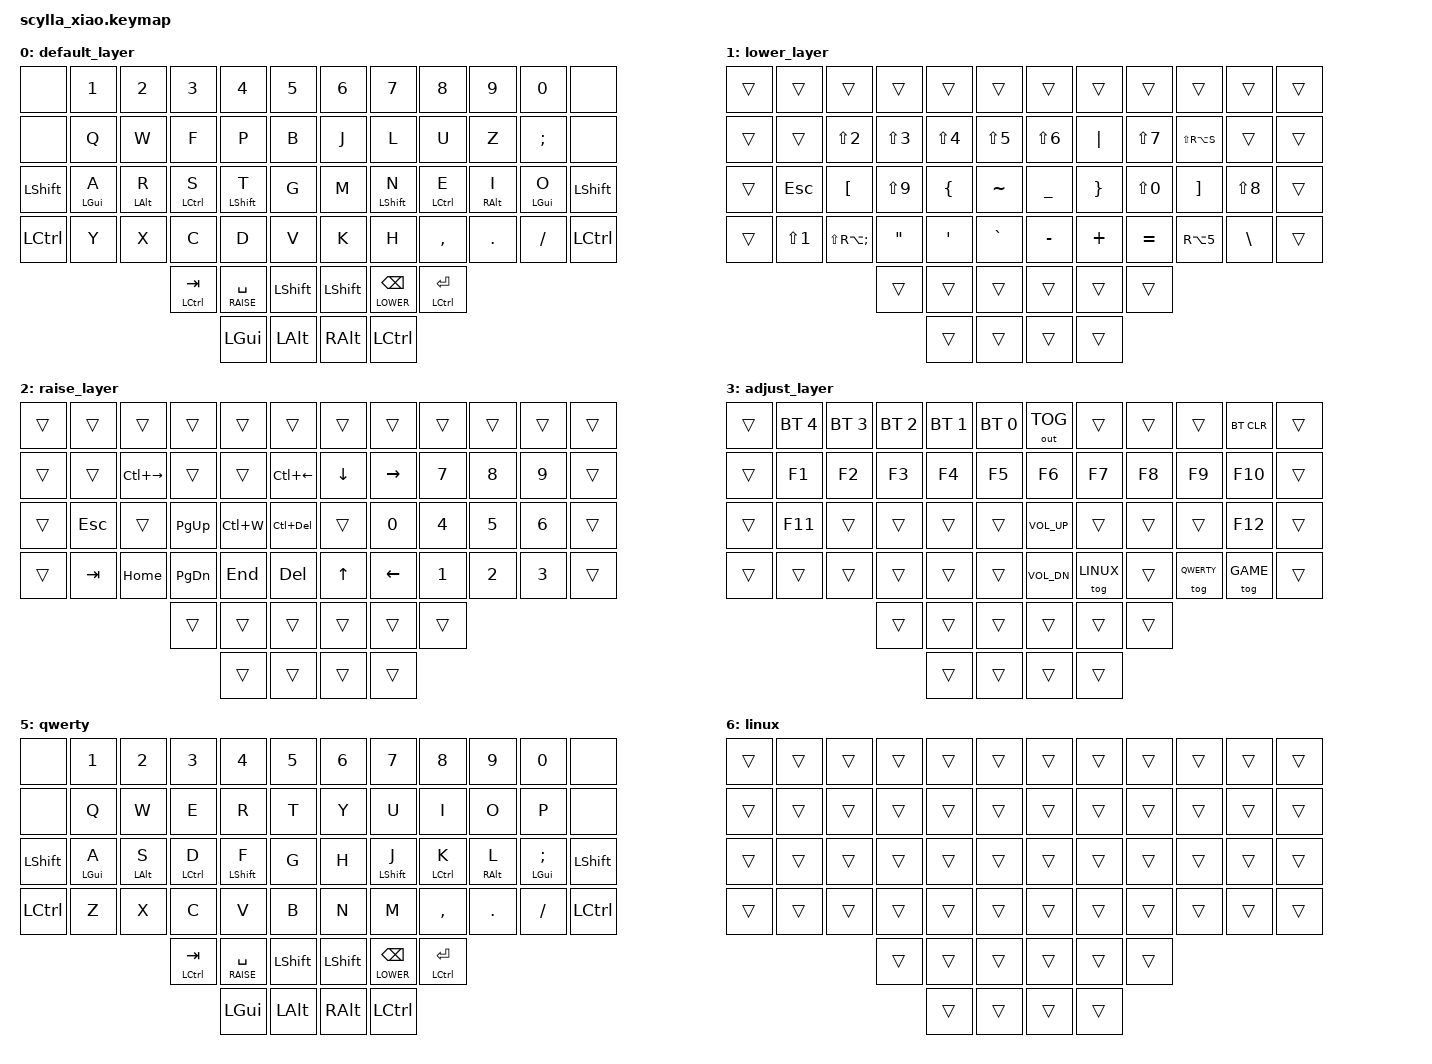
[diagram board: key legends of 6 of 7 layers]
/*
 * Copyright (c) 2020 The ZMK Contributors
 *
 * SPDX-License-Identifier: MIT
 */

#include <behaviors.dtsi>
#include <dt-bindings/zmk/keys.h>
#include <dt-bindings/zmk/outputs.h>
#include <dt-bindings/zmk/bt.h>

#define DEFAULT 0
#define LOWER 1
#define RAISE 2
#define ADJUST 3
#define GAME 4
#define QWERTY 5
#define LINUX 6

#define UMLAUT_AQ <25 13>
#define UMLAUT_SF <27 15>
#define UMLAUT_UE <20 32>
#define UMLAUT_OS <34 22>
#define UMLAUT_MAC_LAYERS <0 1 2 3>
#define UMLAUT_LIN_LAYERS <6>

&lt {
    flavor = "tap-preferred";
    quick-tap-ms = <200>;
};
/ {
    combos {
        compatible = "zmk,combos";
        /* Top corners = bootloader */
        combo_boot {
            key-positions = <0 12>;
            bindings = <&bootloader>;
        };
        #include "umlaut_combos.dtsi"
    };
    conditional_layers {
        compatible = "zmk,conditional-layers";
        tri_layer {
            if-layers = <1 2>;
            then-layer = <3>;
        };
    };
    behaviors {
        #include "umlaut_macros.dtsi"
        hm: homerow_mods {
            compatible = "zmk,behavior-hold-tap";
            label = "HOMEROW_MODS";
            #binding-cells = <2>;
            tapping-term-ms = <170>;
            quick-tap-ms = <100>;
            flavor = "balanced";
            bindings = <&kp>, <&kp>;
        };
        // hm: homerow_mods {
        //     compatible = "zmk,behavior-hold-tap";
        //     label = "HOMEROW_MODS";
        //     #binding-cells = <2>;
        //     tapping-term-ms = <350>;
        //     quick-tap-ms = <0>;
        //     flavor = "balanced";
        //     bindings = <&kp>, <&kp>;
        // };
    };
    keymap {
        compatible = "zmk,keymap";

        default_layer {
// --------------------------------------------------------------------------------------------------------------------------
//                |     |  1  |  2  |  3  |  4  |  5  |                 |  6  |  7  |  8  |  9  |  0  |     |
//                |     |  Q  |  W  |  F  |  P  |  B  |                 |  J  |  L  |  U  |  Z  |  ;  |     |
//                | SFT |  A  |  R  |  S  |  T  |  G  |                 |  M  |  N  |  E  |  I  |  O  | SFT |
//                | CTL |  Y  |  X  |  C  |  D  |  V  |                 |  K  |  H  |  ,  |  .  |  /  | CTL |
//                                  | TAB | SPC | SFT |                 | SFT | BSP | ENT |
//                                        | GUI | ALT |                 | ALT | CTL |

            bindings = <
&none     &kp N1     &kp N2     &kp N3        &kp N4          &kp N5           &kp N6    &kp N7         &kp N8        &kp N9     &kp N0     &none
&none     &kp Q      &kp W      &kp F         &kp P           &kp B            &kp J     &kp L          &kp U         &kp Z      &kp SEMI   &none
&kp LSHFT &hm LGUI A &hm LALT R &hm LCTRL S   &hm LSHFT T     &kp G            &kp M     &hm LSHFT N    &hm LCTRL E   &hm RALT I &hm LGUI O &kp LSHFT
&kp LCTRL &kp Y      &kp X      &kp C         &kp D           &kp V            &kp K     &kp H          &kp COMMA     &kp DOT    &kp FSLH   &kp LCTRL
                                &hm LCTRL TAB &lt RAISE SPACE &kp LSHFT        &kp LSHFT &lt LOWER BSPC &hm LCTRL RET
                                              &kp LGUI        &kp LALT         &kp RALT  &kp LCTRL
            >;
        };

        lower_layer {
// --------------------------------------------------------------------------------------------------------------------------
//                |     |     |     |     |     |     |                 |     |     |     |     |     |     |
//                |     |     |  @  |  #  |  $  |  %  |                 |  ^  |  |  |  &  |  §  |     |     |
//                |     | ESC |  [  |  (  |  {  |  ~  |                 |  _  |  }  |  )  |  ]  |  *  |     |
//                |     |  !  |  °  |  "  |  '  |  `  |                 |  -  |  +  |  =  |  €  |  \  |     |
//                                  |     |     |     |                 |     |     |     |
//                                        |     |     |                 |     |     |

            bindings = <
&trans &trans     &trans           &trans     &trans     &trans         &trans     &trans   &trans     &trans        &trans     &trans
&trans &trans     &kp LS(N2)       &kp LS(N3) &kp LS(N4) &kp LS(N5)     &kp LS(N6) &kp PIPE &kp LS(N7) &kp LS(RA(S)) &trans     &trans
&trans &kp ESC    &kp LBKT         &kp LS(N9) &kp LBRC   &kp TILDE      &kp UNDER  &kp RBRC &kp LS(N0) &kp RBKT      &kp LS(N8) &trans
&trans &kp LS(N1) &kp LS(RA(SEMI)) &kp DQT    &kp SQT    &kp GRAVE      &kp MINUS  &kp PLUS &kp EQUAL  &kp RA(N5)    &kp BSLH   &trans
                                   &trans     &trans     &trans         &trans     &trans   &trans
                                              &trans     &trans         &trans     &trans
            >;
        };

        raise_layer {
// --------------------------------------------------------------------------------------------------------------------------
//                |     |     |     |     |     |     |                |     |     |     |     |     |     |
//                |     |     | WOR |     |     | WOB |                |  v  |  <  |  7  |  8  |  9  |     |
//                |     | ESC |     | PGD | BSW | DEW |                |     |  0  |  4  |  5  |  6  |     |
//                |     | TAB | HOM | PGU | END | DEL |                |  ^  |  >  |  1  |  2  |  3  |     |
//                                  |     |     |     |                |     |     |     |
//                                        |     |     |                |     |     |
            bindings = <
&trans  &trans   &trans        &trans     &trans    &trans          &trans    &trans    &trans  &trans &trans  &trans
&trans  &trans   &kp LC(RIGHT) &trans     &trans    &kp LC(LEFT)    &kp DOWN  &kp RIGHT &kp N7  &kp N8 &kp N9  &trans
&trans  &kp ESC  &trans        &kp PG_UP  &kp LC(W) &kp LC(DEL)     &trans    &kp N0    &kp N4  &kp N5 &kp N6  &trans
&trans  &kp TAB  &kp HOME      &kp PG_DN  &kp END   &kp DEL         &kp UP    &kp LEFT  &kp N1  &kp N2 &kp N3  &trans
                               &trans     &trans    &trans          &trans    &trans    &trans
                                          &trans    &trans          &trans    &trans
            >;
        };

        adjust_layer {
// --------------------------------------------------------------------------------------------------------------------------
//                | bt0 | bt1 | bt2 | bt3 | bt4 | bt5 |                |     |     |     |     |     | btc |
//                |     | F1  | F2  | F3  | F4  | F5  |                | F6  | F7  | F8  | F9  | F10 |b/usb|
//                |     | F11 |     |     |     |     |                | V+  |     |     |     | F12 |     |
//                |     |     |     |     |     |     |                | V-  |     |     | LTQ | LTG |     |
//                                  |     |     |     |                |     |     |     |
//                                        |     |     |                |     |     |
            bindings = <
&trans        &bt BT_SEL 4  &bt BT_SEL 3  &bt BT_SEL 2  &bt BT_SEL 1  &bt BT_SEL 0 &out OUT_TOG  &trans     &trans     &trans      &bt BT_CLR &trans
&trans        &kp F1        &kp F2        &kp F3        &kp F4        &kp F5       &kp F6        &kp F7     &kp F8     &kp F9      &kp F10    &trans
&trans        &kp F11       &trans        &trans        &trans        &trans       &kp K_VOL_UP  &trans     &trans     &trans      &kp F12    &trans
&trans        &trans        &trans        &trans        &trans        &trans       &kp K_VOL_DN  &tog LINUX &trans     &tog QWERTY &tog GAME  &trans
                                          &trans        &trans        &trans       &trans        &trans     &trans
                                                        &trans        &trans       &trans        &trans
            >;
        };

        game {
// ------------------------------------------------------------------------------------------------------------
//               |     | `   |  1  |  2  |  3  |  4  |                |  5  |  6  |  7  |  8  |  9  |     |
//               |     | TAB |  Q  |  W  |  E  |  R  |                |  P  |  L  |  G  |     |     |     |
//               |     | LSH |  A  |  S  |  D  |  F  |                |  I  |  V+ |  E  |  I  |  O  |     |
//               |     | CTL |  Y  |  X  |  C  |  V  | MUTE |  | PP   |  M  |  V- |     |     | LTG |     |
//                           |     | ALT | BSP | SPC | RET  |  |      |     |     |     |     |
            bindings = <
&none  &kp ESC    &kp N1  &kp N2   &kp N3    &kp N4                         &kp N5  &kp N6             &kp N7      &kp N8     &kp N9     &none
&none  &kp TAB    &kp Q   &kp W    &kp E     &kp R                          &kp P   &kp L              &kp G       &none      &none      &none
&none  &kp LSFT   &kp A   &kp S    &kp D     &kp F                          &kp I   &hm LSHFT K_VOL_UP &hm LCTRL E &hm RALT I &hm LGUI O &none
&none  &kp LCTRL  &kp Y   &kp X    &kp C     &kp V     &kp K_MUTE &kp C_PP  &kp M   &kp K_VOL_DN       &none       &none      &tog GAME  &none
                  &none   &kp LALT &kp BSPC  &kp SPACE &kp RET    &none     &none   &none              &none       &none
            >;
        };

        qwerty {
// --------------------------------------------------------------------------------------------------------------------------
//                |     |  1  |  2  |  3  |  4  |  5  |                 |  6  |  7  |  8  |  9  |  0  |     |
//                |     |  Q  |  W  |  E  |  R  |  T  |                 |  Y  |  U  |  I  |  O  |  P  |     |
//                | SFT |  A  |  S  |  D  |  F  |  G  |                 |  H  |  J  |  K  |  L  |  ;  | SFT |
//                | CTL |  Z  |  X  |  C  |  V  |  B  |                 |  N  |  M  |  ,  |  .  |  /  | CTL |
//                                  | TAB | SPC | SFT |                 | SFT | BSP | ENT |
//                                        | GUI | ALT |                 | ALT | CTL |

            bindings = <
&none     &kp N1     &kp N2     &kp N3        &kp N4          &kp N5           &kp N6    &kp N7         &kp N8        &kp N9     &kp N0        &none
&none     &kp Q      &kp W      &kp E         &kp R           &kp T            &kp Y     &kp U          &kp I         &kp O      &kp P         &none
&kp LSHFT &hm LGUI A &hm LALT S &hm LCTRL D   &hm LSHFT F     &kp G            &kp H     &hm LSHFT J    &hm LCTRL K   &hm RALT L &hm LGUI SEMI &kp LSHFT
&kp LCTRL &kp Z      &kp X      &kp C         &kp V           &kp B            &kp N     &kp M          &kp COMMA     &kp DOT    &kp FSLH      &kp LCTRL
                                &hm LCTRL TAB &lt RAISE SPACE &kp LSHFT        &kp LSHFT &lt LOWER BSPC &hm LCTRL RET
                                              &kp LGUI        &kp LALT         &kp RALT  &kp LCTRL
            >;
        };

        linux {
            bindings = <
&trans &trans &trans &trans &trans &trans   &trans &trans &trans &trans &trans &trans
&trans &trans &trans &trans &trans &trans   &trans &trans &trans &trans &trans &trans
&trans &trans &trans &trans &trans &trans   &trans &trans &trans &trans &trans &trans
&trans &trans &trans &trans &trans &trans   &trans &trans &trans &trans &trans &trans
                     &trans &trans &trans   &trans &trans &trans
                            &trans &trans   &trans &trans
            >;
        };
    };
};
